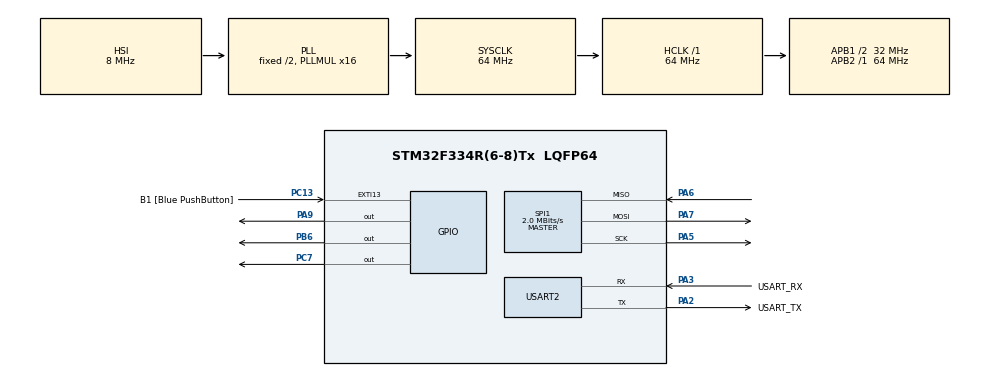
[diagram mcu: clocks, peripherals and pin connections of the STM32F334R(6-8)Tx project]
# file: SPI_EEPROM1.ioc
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Mcu.Family=STM32F3
Mcu.Name=STM32F334R(6-8)Tx
Mcu.Package=LQFP64
NVIC.PriorityGroup=NVIC_PRIORITYGROUP_0
PA13.GPIO_Label=TMS
PA13.Mode=Serial_Wire
PA13.Signal=SYS_JTMS-SWDIO
PA14.GPIO_Label=TCK
PA14.Mode=Serial_Wire
PA14.Signal=SYS_JTCK-SWCLK
PA2.GPIO_Label=USART_TX
PA2.Mode=Asynchronous
PA2.Signal=USART2_TX
PA3.GPIO_Label=USART_RX
PA3.Mode=Asynchronous
PA3.Signal=USART2_RX
PA5.Mode=Full_Duplex_Master
PA5.Signal=SPI1_SCK
PA6.Mode=Full_Duplex_Master
PA6.Signal=SPI1_MISO
PA7.Mode=Full_Duplex_Master
PA7.Signal=SPI1_MOSI
PA9.Signal=GPIO_Output
PB3.GPIO_Label=SWO
PB3.Signal=SYS_JTDO-TRACESWO
PB6.Signal=GPIO_Output
PC13.GPIO_Label=B1 [Blue PushButton]
PC13.GPIO_ModeDefaultEXTI=GPIO_MODE_IT_FALLING
PC13.Signal=GPXTI13
PC14\ /\ OSC32_IN.Mode=LSE-External-Oscillator
PC14\ /\ OSC32_IN.Signal=RCC_OSC32_IN
PC15\ /\ OSC32_OUT.GPIO_Label=RCC_OSC32_OUT
PC15\ /\ OSC32_OUT.Mode=LSE-External-Oscillator
PC15\ /\ OSC32_OUT.Signal=RCC_OSC32_OUT
PC7.Signal=GPIO_Output
PF0\ /\ OSC_IN.Mode=HSE-External-Clock-Source
PF0\ /\ OSC_IN.Signal=RCC_OSC_IN
PF1\ /\ OSC_OUT.Signal=RCC_OSC_OUT
ProjectManager.HeapSize=0x200
ProjectManager.StackSize=0x400
ProjectManager.TargetToolchain=TrueSTUDIO
RCC.AHBFreq_Value=64000000
RCC.APB1CLKDivider=RCC_HCLK_DIV2
RCC.APB1Freq_Value=32000000
RCC.APB1TimFreq_Value=64000000
RCC.APB2Freq_Value=64000000
RCC.APB2TimFreq_Value=64000000
RCC.CortexFreq_Value=64000000
RCC.FLatency-AdvancedSettings=FLASH_LATENCY_2
RCC.HCLKFreq_Value=64000000
RCC.HSE_VALUE=8000000
RCC.HSI_VALUE=8000000
RCC.PLLMUL=RCC_PLL_MUL16
RCC.SYSCLKFreq_VALUE=64000000
RCC.SYSCLKSourceVirtual=RCC_SYSCLKSOURCE_PLLCLK
SPI1.BaudRatePrescaler=SPI_BAUDRATEPRESCALER_32
SPI1.CalculateBaudRate=2.0 MBits/s
SPI1.DataSize=SPI_DATASIZE_8BIT
SPI1.Direction=SPI_DIRECTION_2LINES
SPI1.Mode=SPI_MODE_MASTER
SPI1.VirtualType=VM_MASTER
USART2.VirtualMode-Asynchronous=VM_ASYNC
board=NUCLEO-F334R8

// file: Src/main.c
/* USER CODE BEGIN Header */
/**
  ******************************************************************************
  * @file           : main.c
  * @brief          : Main program body
  ******************************************************************************
  ** This notice applies to any and all portions of this file
  * that are not between comment pairs USER CODE BEGIN and
  * USER CODE END. Other portions of this file, whether
  * inserted by the user or by software development tools
  * are owned by their respective copyright owners.
  *
  * COPYRIGHT(c) 2019 STMicroelectronics
  *
  * Redistribution and use in source and binary forms, with or without modification,
  * are permitted provided that the following conditions are met:
  *   1. Redistributions of source code must retain the above copyright notice,
  *      this list of conditions and the following disclaimer.
  *   2. Redistributions in binary form must reproduce the above copyright notice,
  *      this list of conditions and the following disclaimer in the documentation
  *      and/or other materials provided with the distribution.
  *   3. Neither the name of STMicroelectronics nor the names of its contributors
  *      may be used to endorse or promote products derived from this software
  *      without specific prior written permission.
  *
  * THIS SOFTWARE IS PROVIDED BY THE COPYRIGHT HOLDERS AND CONTRIBUTORS "AS IS"
  * AND ANY EXPRESS OR IMPLIED WARRANTIES, INCLUDING, BUT NOT LIMITED TO, THE
  * IMPLIED WARRANTIES OF MERCHANTABILITY AND FITNESS FOR A PARTICULAR PURPOSE ARE
  * DISCLAIMED. IN NO EVENT SHALL THE COPYRIGHT HOLDER OR CONTRIBUTORS BE LIABLE
  * FOR ANY DIRECT, INDIRECT, INCIDENTAL, SPECIAL, EXEMPLARY, OR CONSEQUENTIAL
  * DAMAGES (INCLUDING, BUT NOT LIMITED TO, PROCUREMENT OF SUBSTITUTE GOODS OR
  * SERVICES; LOSS OF USE, DATA, OR PROFITS; OR BUSINESS INTERRUPTION) HOWEVER
  * CAUSED AND ON ANY THEORY OF LIABILITY, WHETHER IN CONTRACT, STRICT LIABILITY,
  * OR TORT (INCLUDING NEGLIGENCE OR OTHERWISE) ARISING IN ANY WAY OUT OF THE USE
  * OF THIS SOFTWARE, EVEN IF ADVISED OF THE POSSIBILITY OF SUCH DAMAGE.
  *
  ******************************************************************************
  */
/* USER CODE END Header */

#include "main.h"
#include "spi.h"
#include "usart.h"
#include "gpio.h"

#include "STM32_EEPROM_SPI.h"

void SystemClock_Config(void);

int main(void)
{
	  uint8_t len = 0;
	  uint8_t buffout[4];
	  uint8_t TxBuffer[32] = "TEST THIS COOL EEPIOI STM SPI ++";
	  uint8_t RxBuffer[32];
	  uint8_t Banner[] = "hola";

  /* MCU Configuration--------------------------------------------------------*/

  /* Reset of all peripherals, Initializes the Flash interface and the Systick. */
  HAL_Init();

  /* Configure the system clock */
  SystemClock_Config();

  /* USER CODE BEGIN SysInit */
//h
  /* USER CODE END SysInit */

  /* Initialize all configured peripherals */
  MX_GPIO_Init();
  MX_USART2_UART_Init();
  MX_SPI1_Init();
  EEPROM_SPI_INIT();
  HAL_UART_Transmit(&huart2, &Banner,4, 15);
  len = sprintf(buffout,"\n");
  HAL_UART_Transmit(&huart2, &buffout,len, 15);
  EEPROM_SPI_WriteBuffer(&hspi1,TxBuffer, (uint16_t)0x01, (uint16_t)32);

  /* Infinite loop */
  while (1)
  {
	  	HAL_Delay(3000);
		EEPROM_SPI_ReadBuffer(&hspi1,RxBuffer, (uint16_t)0x01, (uint16_t)32);
		HAL_UART_Transmit(&huart2, &RxBuffer,32, 15);
		len = sprintf(buffout,"\n");
		HAL_UART_Transmit(&huart2, &buffout,len, 15);
		HAL_GPIO_TogglePin(GPIOC, GPIO_PIN_2);

		//HAL_Delay(3000);
  }
}

void SystemClock_Config(void)
{
  RCC_OscInitTypeDef RCC_OscInitStruct = {0};
  RCC_ClkInitTypeDef RCC_ClkInitStruct = {0};

  /**Initializes the CPU, AHB and APB busses clocks
  */
  RCC_OscInitStruct.OscillatorType = RCC_OSCILLATORTYPE_HSI;
  RCC_OscInitStruct.HSIState = RCC_HSI_ON;
  RCC_OscInitStruct.HSICalibrationValue = RCC_HSICALIBRATION_DEFAULT;
  RCC_OscInitStruct.PLL.PLLState = RCC_PLL_ON;
  RCC_OscInitStruct.PLL.PLLSource = RCC_PLLSOURCE_HSI;
  RCC_OscInitStruct.PLL.PLLMUL = RCC_PLL_MUL16;
  if (HAL_RCC_OscConfig(&RCC_OscInitStruct) != HAL_OK)
  {
    Error_Handler();
  }
  /**Initializes the CPU, AHB and APB busses clocks
  */
  RCC_ClkInitStruct.ClockType = RCC_CLOCKTYPE_HCLK|RCC_CLOCKTYPE_SYSCLK
                              |RCC_CLOCKTYPE_PCLK1|RCC_CLOCKTYPE_PCLK2;
  RCC_ClkInitStruct.SYSCLKSource = RCC_SYSCLKSOURCE_PLLCLK;
  RCC_ClkInitStruct.AHBCLKDivider = RCC_SYSCLK_DIV1;
  RCC_ClkInitStruct.APB1CLKDivider = RCC_HCLK_DIV2;
  RCC_ClkInitStruct.APB2CLKDivider = RCC_HCLK_DIV1;

  if (HAL_RCC_ClockConfig(&RCC_ClkInitStruct, FLASH_LATENCY_2) != HAL_OK)
  {
    Error_Handler();
  }
}

void Error_Handler(void)
{
}

/************************ (C) COPYRIGHT STMicroelectronics *****END OF FILE****/
